# R7FA4L1BD register map
Vendor: Renesas Electronics Corporation; Series: RA4; File version: 0.90.02
CPU: CM33 r0p4, little endian, MPU, FPU, VTOR, 4 interrupt priority bits, 96 interrupts
Registers are 32-bit, read-write, reset 0x0 unless marked. A register's access mark holds for its fields unless they carry their own. Offsets are from the block's base; [hi:lo] are bit positions.

## IWDT — Independent Watchdog Timer
Base 0x40083200
0x00 IWDTRR 8-bit reset 0xFF — IWDT Refresh Register
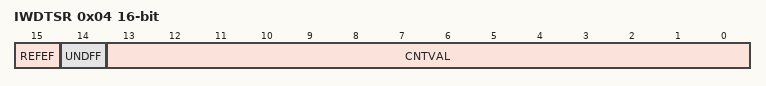
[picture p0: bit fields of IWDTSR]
0x04 IWDTSR 16-bit — IWDT Status Register
  [15] REFEF — Refresh Error Flag
  [14] UNDFF — Underflow Flag
  [13:0] CNTVAL ro — Down,counter Value

## WDT — Watchdog Timer
Base 0x40083400
0x00 WDTRR 8-bit reset 0xFF — WDT Refresh Register
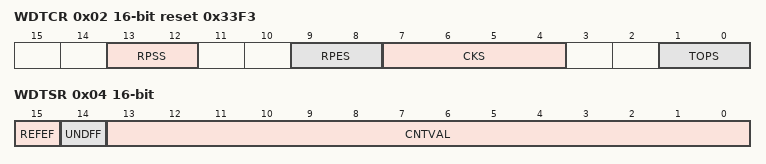
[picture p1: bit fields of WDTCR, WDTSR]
0x02 WDTCR 16-bit reset 0x33F3 — WDT Control Register
  [13:12] RPSS — Window Start Position Select
  [9:8] RPES — Window End Position Select
  [7:4] CKS — Clock Division Ratio Select
  [1:0] TOPS — Timeout Period Select
0x04 WDTSR 16-bit — WDT Status Register
  [15] REFEF — Refresh Error Flag
  [14] UNDFF — Underflow Flag
  [13:0] CNTVAL ro — Down,Counter Value
0x06 WDTRCR 8-bit reset 0x80 — WDT Reset Control Register
  [7] RSTIRQS — WDT Behavior Selection
0x08 WDTCSTPR 8-bit reset 0x80 — WDT Count Stop Control Register
  [7] SLCSTP — Sleep,Mode Count Stop Control Register

## CAC — Clock Frequency Accuracy Measurement Circuit
Base 0x40083600
0x00 CACR0 8-bit — CAC Control Register 0
  [0] CFME — Clock Frequency Measurement Enable
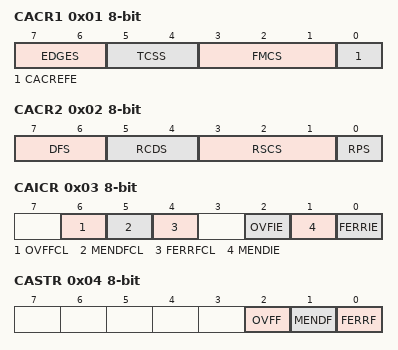
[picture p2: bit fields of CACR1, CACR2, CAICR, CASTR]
0x01 CACR1 8-bit — CAC Control Register 1
  [7:6] EDGES — Valid Edge Select
  [5:4] TCSS — Timer Count Clock Source Select
  [3:1] FMCS — Measurement Target Clock Select
  [0] CACREFE — CACREF Pin Input Enable
0x02 CACR2 8-bit — CAC Control Register 2
  [7:6] DFS — Digital Filter Select
  [5:4] RCDS — Measurement Reference Clock Frequency Division Ratio Select
  [3:1] RSCS — Measurement Reference Clock Select
  [0] RPS — Reference Signal Select
0x03 CAICR 8-bit — CAC Interrupt Control Register
  [6] OVFFCL wo — OVFF Clear
  [5] MENDFCL wo — MENDF Clear
  [4] FERRFCL wo — FERRF Clear
  [2] OVFIE — Overflow Interrupt Request Enable
  [1] MENDIE — Measurement End Interrupt Request Enable
  [0] FERRIE — Frequency Error Interrupt Request Enable
0x04 CASTR 8-bit ro — CAC Status Register
  [2] OVFF — Overflow Flag
  [1] MENDF — Measurement End Flag
  [0] FERRF — Frequency Error Flag
0x06 CAULVR 16-bit — CAC Upper,Limit Value Setting Register
0x08 CALLVR 16-bit — CAC Lower,Limit Value Setting Register
0x0A CACNTBR 16-bit ro — CAC Counter Buffer Register

## MSTP — Module Stop Control
Base 0x40084000
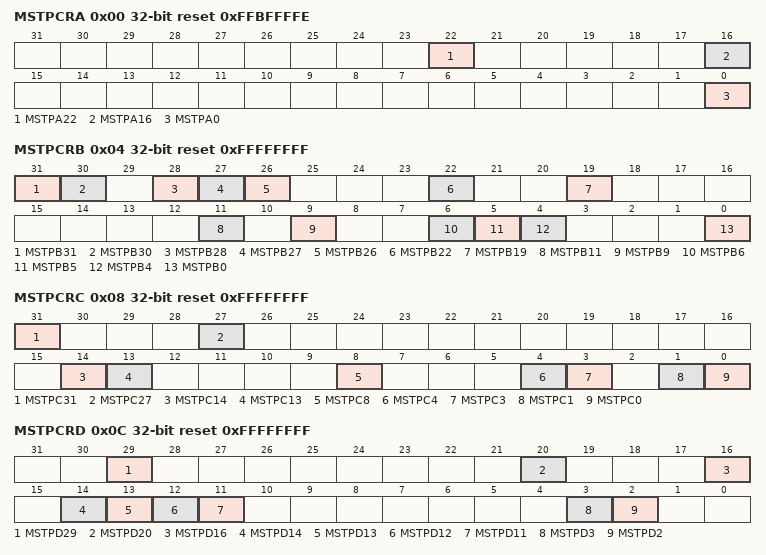
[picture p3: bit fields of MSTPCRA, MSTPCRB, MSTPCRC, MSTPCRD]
0x00 MSTPCRA reset 0xFFBFFFFE — Module Stop Control Register A
  [22] MSTPA22 — DMA Controller/Data Transfer Controller Module Stop
  [16] MSTPA16 — Sub Oscillation Stop Detection Module Stop
  [0] MSTPA0 — SRAM0 Module Stop
0x04 MSTPCRB reset 0xFFFFFFFF — Module Stop Control Register B
  [31] MSTPB31 — Serial Communication Interface 0 Module Stop
  [30] MSTPB30 — Serial Communication Interface 1 Module Stop
  [28] MSTPB28 — Serial Communication Interface 3 Module Stop
  [27] MSTPB27 — Serial Communication Interface 4 Module Stop
  [26] MSTPB26 — Serial Communication Interface 5 Module Stop
  [22] MSTPB22 — Serial Communication Interface 9 Module Stop
  [19] MSTPB19 — Serial Peripheral Interface 0 Module Stop
  [11] MSTPB11 — Universal Serial Bus 2.0 FS Interface Module Stop
  [9] MSTPB9 — I2C Bus Interface 0 Module Stop
  [6] MSTPB6 — Quad Serial Peripheral Interface Module Stop
  [5] MSTPB5 — IrDA Interface Module Stop
  [4] MSTPB4 — I3C Bus Interface Module Stop
  [0] MSTPB0 — Serial Interface UARTA Module Stop
0x08 MSTPCRC reset 0xFFFFFFFF — Module Stop Control Register C
  [31] MSTPC31 — RSIP,E11A Module Stop
  [27] MSTPC27 — Controller Area Network with Flexible Data,Rate Module Stop
  [14] MSTPC14 — Event Link Controller Module Stop
  [13] MSTPC13 — Data Operation Circuit Module Stop
  [8] MSTPC8 — Serial Sound Interface Enhanced Module Stop
  [4] MSTPC4 — Segment LCD Controller Module Stop
  [3] MSTPC3 — Capacitive Touch Sensing Unit Module Stop
  [1] MSTPC1 — Cyclic Redundancy Check Calculator Module Stop
  [0] MSTPC0 — Clock Frequency Accuracy Measurement Circuit Module Stop
0x0C MSTPCRD reset 0xFFFFFFFF — Module Stop Control Register D
  [29] MSTPD29 — Low,Power Analog Comparator Module Stop
  [20] MSTPD20 — 12-bit D/A Converter Module Stop
  [16] MSTPD16 — 12-bit A/D Converter 0 Module Stop
  [14] MSTPD14 — Port Output Enable for GPT Group A Module Stop
  [13] MSTPD13 — Port Output Enable for GPT Group B Module Stop
  [12] MSTPD12 — Port Output Enable for GPT Group C Module Stop
  [11] MSTPD11 — Port Output Enable for GPT Group D Module Stop
  [3] MSTPD3 — Low Power Asynchronous General Purpose Timer 0 Module Stop
  [2] MSTPD2 — Low Power Asynchronous General Purpose Timer 1 Module Stop
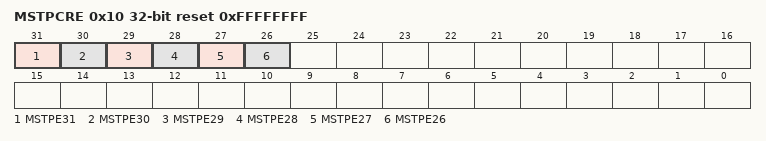
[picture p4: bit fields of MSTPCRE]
0x10 MSTPCRE reset 0xFFFFFFFF — Module Stop Control Register E
  [31] MSTPE31 — GPT0 Module Stop
  [30] MSTPE30 — GPT1 Module Stop
  [29] MSTPE29 — GPT2 Module Stop
  [28] MSTPE28 — GPT3 Module Stop
  [27] MSTPE27 — GPT4 Module Stop
  [26] MSTPE26 — GPT5 Module Stop
